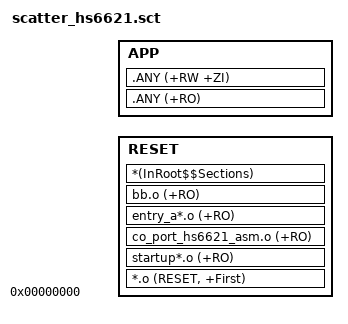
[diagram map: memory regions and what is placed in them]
#! armcc -E
; ***************************************************************
; *** Scatter-Loading Description File generated by Huntersun ***
; ***************************************************************

RAM_LOAD 0x00000000 0x00040000
{
    RESET 0x00000000
    {
        *.o (RESET, +First)
        startup*.o (+RO)
        co_port_hs6621_asm.o (+RO)
        entry_a*.o (+RO)
        bb.o (+RO)
        *(InRoot$$Sections)
    }

    APP +0
    {
        .ANY (+RO)
        .ANY (+RW +ZI)
    }
}

ScatterAssert(ImageLimit(RESET) < 0x00002000)
ScatterAssert(ImageLimit(APP)   < 0x0003e988)

